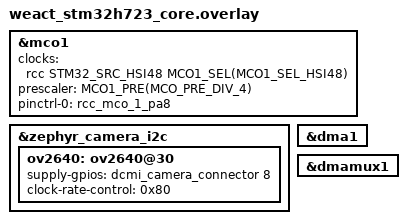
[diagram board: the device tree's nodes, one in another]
/*
 * SPDX-FileCopyrightText: Copyright The Zephyr Project Contributors
 * SPDX-License-Identifier: Apache-2.0
 */

/*
 * AHB clocks must respect the minimum ratio AHB / DCMI_PIXCLK of 2.5
 * (AN5020 - Rev 3). The OV2640 PCLK is around 72 MHz for QQVGA
 * (160x120) with MCO1_SEL_HSI48 and MCO_PRE_DIV_4. With SYSCLK 550 MHz
 * and hpre = 2, HCLK is 275 MHz (ratio ~3.8).
 */
&mco1 {
	clocks = <&rcc STM32_SRC_HSI48 MCO1_SEL(MCO1_SEL_HSI48)>;
	prescaler = <MCO1_PRE(MCO_PRE_DIV_4)>;
	pinctrl-0 = <&rcc_mco_1_pa8>;
	pinctrl-names = "default";
	status = "okay";
};

&zephyr_camera_i2c {
	ov2640: ov2640@30 {
		supply-gpios = <&dcmi_camera_connector 8 GPIO_ACTIVE_HIGH>;
		clock-rate-control = <0x80>;
	};
};

&dma1 {
	status = "okay";
};

&dmamux1 {
	status = "okay";
};
